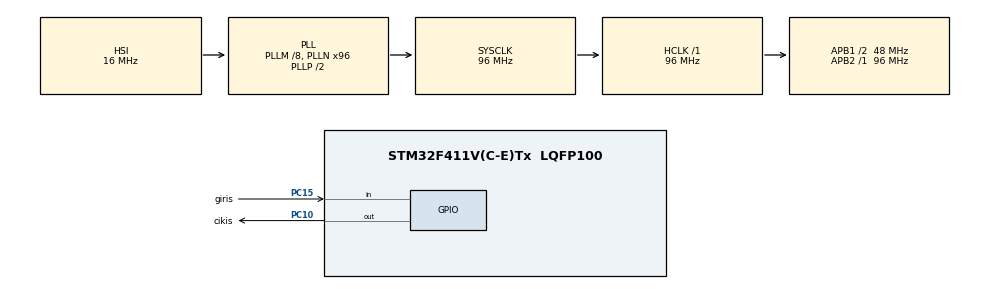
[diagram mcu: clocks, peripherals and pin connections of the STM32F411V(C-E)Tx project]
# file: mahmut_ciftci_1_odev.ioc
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Mcu.Family=STM32F4
Mcu.Name=STM32F411V(C-E)Tx
Mcu.Package=LQFP100
NVIC.PriorityGroup=NVIC_PRIORITYGROUP_4
NVIC.TIM2_IRQn=true\:0\:0\:false\:false\:true\:true\:true
PA13.Mode=Serial_Wire
PA13.Signal=SYS_JTMS-SWDIO
PA14.Mode=Serial_Wire
PA14.Signal=SYS_JTCK-SWCLK
PC10.GPIO_Label=cikis
PC10.Signal=GPIO_Output
PC15-OSC32_OUT.GPIO_Label=giris
PC15-OSC32_OUT.Signal=GPIO_Input
PH0\ -\ OSC_IN.Mode=HSE-External-Oscillator
PH0\ -\ OSC_IN.Signal=RCC_OSC_IN
PH1\ -\ OSC_OUT.Mode=HSE-External-Oscillator
PH1\ -\ OSC_OUT.Signal=RCC_OSC_OUT
ProjectManager.HeapSize=0x200
ProjectManager.StackSize=0x400
ProjectManager.TargetToolchain=STM32CubeIDE
RCC.48MHZClocksFreq_Value=48000000
RCC.AHBFreq_Value=96000000
RCC.APB1CLKDivider=RCC_HCLK_DIV2
RCC.APB1Freq_Value=48000000
RCC.APB1TimFreq_Value=96000000
RCC.APB2Freq_Value=96000000
RCC.APB2TimFreq_Value=96000000
RCC.CortexFreq_Value=96000000
RCC.HCLKFreq_Value=96000000
RCC.HSE_VALUE=25000000
RCC.HSI_VALUE=16000000
RCC.LSE_VALUE=32768
RCC.PLLM=8
RCC.PLLN=96
RCC.SYSCLKFreq_VALUE=96000000
RCC.SYSCLKSource=RCC_SYSCLKSOURCE_PLLCLK
RCC.VCOOutputFreq_Value=192000000
TIM2.Period=62499
TIM2.Prescaler=399
VP_TIM2_VS_ClockSourceINT.Mode=Internal
board=custom

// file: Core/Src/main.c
/* USER CODE BEGIN Header */
/**
  ******************************************************************************
  * @file           : main.c
  * @brief          : Main program body
  ******************************************************************************
  * @attention
  *
  * <h2><center>&copy; Copyright (c) 2023 STMicroelectronics.
  * All rights reserved.</center></h2>
  *
  * This software component is licensed by ST under BSD 3-Clause license,
  * the "License"; You may not use this file except in compliance with the
  * License. You may obtain a copy of the License at:
  *                        opensource.org/licenses/BSD-3-Clause
  *
  ******************************************************************************
  */
/* USER CODE END Header */

#include "main.h"

TIM_HandleTypeDef htim2;

/* USER CODE BEGIN PV */

int bayrak = 0;
int gelen = 0;

/* USER CODE END PV */

void SystemClock_Config(void);
static void MX_GPIO_Init(void);
static void MX_TIM2_Init(void);

int main(void)
{

  /* MCU Configuration--------------------------------------------------------*/

  /* Reset of all peripherals, Initializes the Flash interface and the Systick. */
  HAL_Init();

  /* Configure the system clock */
  SystemClock_Config();

  /* Initialize all configured peripherals */
  MX_GPIO_Init();
  MX_TIM2_Init();
  /* USER CODE BEGIN 2 */
  HAL_TIM_Base_Start_IT(&htim2);
  HAL_TIM_Base_Start(&htim2);
  /* USER CODE END 2 */

  /* Infinite loop */
  while (1)
  {

    /* USER CODE BEGIN 3 */
	  if(bayrak== 1){
			  HAL_GPIO_WritePin(GPIOC, cikis_Pin , GPIO_PIN_SET);

		   }else {
			  HAL_GPIO_WritePin(GPIOC,cikis_Pin , GPIO_PIN_RESET);
		   }

		  gelen = HAL_GPIO_ReadPin(GPIOC, giris_Pin);

  }
  /* USER CODE END 3 */
}

void SystemClock_Config(void)
{
  RCC_OscInitTypeDef RCC_OscInitStruct = {0};
  RCC_ClkInitTypeDef RCC_ClkInitStruct = {0};

  /** Configure the main internal regulator output voltage
  */
  __HAL_RCC_PWR_CLK_ENABLE();
  __HAL_PWR_VOLTAGESCALING_CONFIG(PWR_REGULATOR_VOLTAGE_SCALE1);
  /** Initializes the CPU, AHB and APB busses clocks
  */
  RCC_OscInitStruct.OscillatorType = RCC_OSCILLATORTYPE_HSI;
  RCC_OscInitStruct.HSIState = RCC_HSI_ON;
  RCC_OscInitStruct.HSICalibrationValue = RCC_HSICALIBRATION_DEFAULT;
  RCC_OscInitStruct.PLL.PLLState = RCC_PLL_ON;
  RCC_OscInitStruct.PLL.PLLSource = RCC_PLLSOURCE_HSI;
  RCC_OscInitStruct.PLL.PLLM = 8;
  RCC_OscInitStruct.PLL.PLLN = 96;
  RCC_OscInitStruct.PLL.PLLP = RCC_PLLP_DIV2;
  RCC_OscInitStruct.PLL.PLLQ = 4;
  if (HAL_RCC_OscConfig(&RCC_OscInitStruct) != HAL_OK)
  {
    Error_Handler();
  }
  /** Initializes the CPU, AHB and APB busses clocks
  */
  RCC_ClkInitStruct.ClockType = RCC_CLOCKTYPE_HCLK|RCC_CLOCKTYPE_SYSCLK
                              |RCC_CLOCKTYPE_PCLK1|RCC_CLOCKTYPE_PCLK2;
  RCC_ClkInitStruct.SYSCLKSource = RCC_SYSCLKSOURCE_PLLCLK;
  RCC_ClkInitStruct.AHBCLKDivider = RCC_SYSCLK_DIV1;
  RCC_ClkInitStruct.APB1CLKDivider = RCC_HCLK_DIV2;
  RCC_ClkInitStruct.APB2CLKDivider = RCC_HCLK_DIV1;

  if (HAL_RCC_ClockConfig(&RCC_ClkInitStruct, FLASH_LATENCY_3) != HAL_OK)
  {
    Error_Handler();
  }
}

static void MX_TIM2_Init(void)
{

  TIM_ClockConfigTypeDef sClockSourceConfig = {0};
  TIM_MasterConfigTypeDef sMasterConfig = {0};

  htim2.Instance = TIM2;
  htim2.Init.Prescaler = 399;
  htim2.Init.CounterMode = TIM_COUNTERMODE_UP;
  htim2.Init.Period = 62499;
  htim2.Init.ClockDivision = TIM_CLOCKDIVISION_DIV1;
  htim2.Init.AutoReloadPreload = TIM_AUTORELOAD_PRELOAD_DISABLE;
  if (HAL_TIM_Base_Init(&htim2) != HAL_OK)
  {
    Error_Handler();
  }
  sClockSourceConfig.ClockSource = TIM_CLOCKSOURCE_INTERNAL;
  if (HAL_TIM_ConfigClockSource(&htim2, &sClockSourceConfig) != HAL_OK)
  {
    Error_Handler();
  }
  sMasterConfig.MasterOutputTrigger = TIM_TRGO_RESET;
  sMasterConfig.MasterSlaveMode = TIM_MASTERSLAVEMODE_DISABLE;
  if (HAL_TIMEx_MasterConfigSynchronization(&htim2, &sMasterConfig) != HAL_OK)
  {
    Error_Handler();
  }

}

static void MX_GPIO_Init(void)
{
  GPIO_InitTypeDef GPIO_InitStruct = {0};

  /* GPIO Ports Clock Enable */
  __HAL_RCC_GPIOC_CLK_ENABLE();
  __HAL_RCC_GPIOH_CLK_ENABLE();
  __HAL_RCC_GPIOA_CLK_ENABLE();

  /*Configure GPIO pin Output Level */
  HAL_GPIO_WritePin(cikis_GPIO_Port, cikis_Pin, GPIO_PIN_RESET);

  /*Configure GPIO pin : giris_Pin */
  GPIO_InitStruct.Pin = giris_Pin;
  GPIO_InitStruct.Mode = GPIO_MODE_INPUT;
  GPIO_InitStruct.Pull = GPIO_NOPULL;
  HAL_GPIO_Init(giris_GPIO_Port, &GPIO_InitStruct);

  /*Configure GPIO pin : cikis_Pin */
  GPIO_InitStruct.Pin = cikis_Pin;
  GPIO_InitStruct.Mode = GPIO_MODE_OUTPUT_PP;
  GPIO_InitStruct.Pull = GPIO_NOPULL;
  GPIO_InitStruct.Speed = GPIO_SPEED_FREQ_LOW;
  HAL_GPIO_Init(cikis_GPIO_Port, &GPIO_InitStruct);

}

void Error_Handler(void)
{
}

/************************ (C) COPYRIGHT STMicroelectronics *****END OF FILE****/
